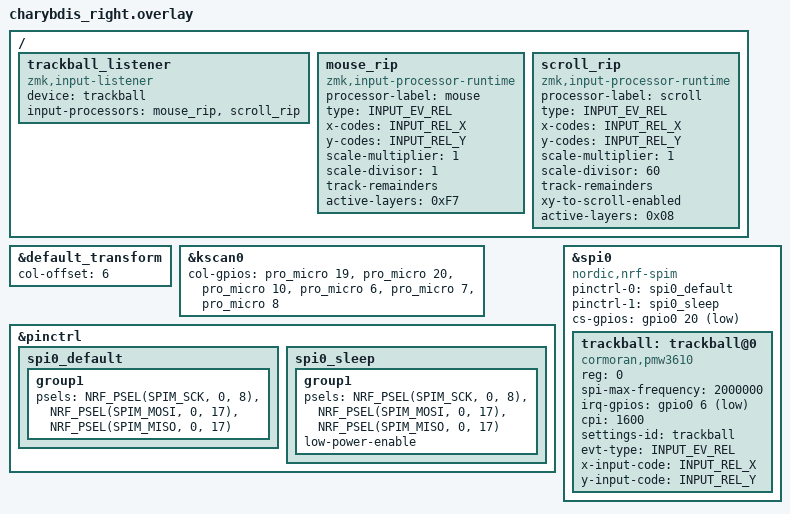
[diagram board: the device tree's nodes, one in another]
/* charybdis_right.overlay -- central + trackball (DYA Studio L2) */

#include "charybdis.dtsi"
#include <dt-bindings/input/input-event-codes.h>
#include <input/processors.dtsi>
#include <input/processors/runtime-input-processor.dtsi>
#include <behaviors/runtime-input-processor.dtsi>

&default_transform {
    col-offset = <6>;
};

&kscan0 {
    col-gpios
        = <&pro_micro 19 (GPIO_ACTIVE_HIGH | GPIO_PULL_DOWN)>
        , <&pro_micro 20 (GPIO_ACTIVE_HIGH | GPIO_PULL_DOWN)>
        , <&pro_micro 10 (GPIO_ACTIVE_HIGH | GPIO_PULL_DOWN)>
        , <&pro_micro  6 (GPIO_ACTIVE_HIGH | GPIO_PULL_DOWN)>
        , <&pro_micro  7 (GPIO_ACTIVE_HIGH | GPIO_PULL_DOWN)>
        , <&pro_micro  8 (GPIO_ACTIVE_HIGH | GPIO_PULL_DOWN)>
        ;
};

/* ---------------- trackball bus ---------------- */
&pinctrl {
    spi0_default: spi0_default {
        group1 {
            psels = <NRF_PSEL(SPIM_SCK, 0, 8)>,
                <NRF_PSEL(SPIM_MOSI, 0, 17)>,
                <NRF_PSEL(SPIM_MISO, 0, 17)>;
        };
    };

    spi0_sleep: spi0_sleep {
        group1 {
            psels = <NRF_PSEL(SPIM_SCK, 0, 8)>,
                <NRF_PSEL(SPIM_MOSI, 0, 17)>,
                <NRF_PSEL(SPIM_MISO, 0, 17)>;
            low-power-enable;
        };
    };
};

&spi0 {
    status = "okay";
    compatible = "nordic,nrf-spim";
    pinctrl-0 = <&spi0_default>;
    pinctrl-1 = <&spi0_sleep>;
    pinctrl-names = "default", "sleep";
    cs-gpios = <&gpio0 20 GPIO_ACTIVE_LOW>;

    trackball: trackball@0 {
        status = "okay";
        compatible = "cormoran,pmw3610";
        reg = <0>;
        spi-max-frequency = <2000000>;
        irq-gpios = <&gpio0 6 (GPIO_ACTIVE_LOW | GPIO_PULL_UP)>;

        cpi = <1600>;
        settings-id = "trackball";

        evt-type = <INPUT_EV_REL>;
        x-input-code = <INPUT_REL_X>;
        y-input-code = <INPUT_REL_Y>;

        /delete-property/ snipe-layers;
        /delete-property/ scroll-layers;
        /delete-property/ automouse-layer;
        /delete-property/ snipe-cpi;
        /delete-property/ scroll-tick;
    };
};

/ {
    trackball_listener {
        compatible = "zmk,input-listener";
        device = <&trackball>;
        input-processors = <&mouse_rip &scroll_rip>;
    };

    mouse_rip: mouse_rip {
        compatible = "zmk,input-processor-runtime";
        processor-label = "mouse";
        type = <INPUT_EV_REL>;
        x-codes = <INPUT_REL_X>;
        y-codes = <INPUT_REL_Y>;
        scale-multiplier = <1>;
        scale-divisor = <1>;
        track-remainders;
        active-layers = <0xF7>;   /* bits 0-7 except bit 3: normal on all but scroll */
        #input-processor-cells = <0>;
    };

    scroll_rip: scroll_rip {
        compatible = "zmk,input-processor-runtime";
        processor-label = "scroll";
        type = <INPUT_EV_REL>;
        x-codes = <INPUT_REL_X>;
        y-codes = <INPUT_REL_Y>;
        scale-multiplier = <1>;
        scale-divisor = <60>;
        track-remainders;
        xy-to-scroll-enabled;     /* THE conversion - must be present */
        active-layers = <0x08>;   /* bit 3 = scroll_gate */
        #input-processor-cells = <0>;
    };
};
